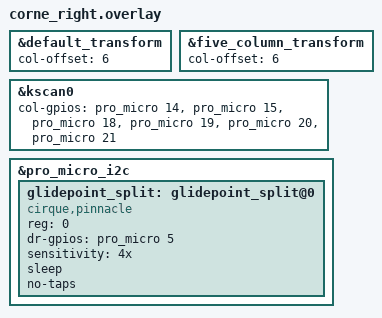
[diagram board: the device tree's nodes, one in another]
/*
 * Copyright (c) 2020 Pete Johanson
 *
 * SPDX-License-Identifier: MIT
 */

#include "corne.dtsi"

&default_transform {
    col-offset = <6>;
};

&five_column_transform {
    col-offset = <6>;
};

&kscan0 {
    col-gpios
        = <&pro_micro 14 GPIO_ACTIVE_HIGH>
        , <&pro_micro 15 GPIO_ACTIVE_HIGH>
        , <&pro_micro 18 GPIO_ACTIVE_HIGH>
        , <&pro_micro 19 GPIO_ACTIVE_HIGH>
        , <&pro_micro 20 GPIO_ACTIVE_HIGH>
        , <&pro_micro 21 GPIO_ACTIVE_HIGH>
        ;
};

&pro_micro_i2c {
    status = "okay";

    glidepoint_split: glidepoint_split@0 {
        compatible = "cirque,pinnacle";
        reg = <0>;
        status = "okay";
        dr-gpios = <&pro_micro 5 (GPIO_ACTIVE_HIGH)>; // DR pin on cirque is always &vik_conn 5

        sensitivity = "4x";
        sleep;
        no-taps;
    };
};

// / {
//     glidepoint_input: glidepoint_input {
//         compatible = "zmk,input-listener";
//         device = <&glidepoint>;

//         // Options for cirque, to be defined in the keyboard shield
//         // input-processors = <&xy_transform (INPUT_TRANSFORM_XY_SWAP | INPUT_TRANSFORM_X_INVERT | INPUT_TRANSFORM_Y_INVERT) &xy_scaler 3 2>;
//     };
// };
